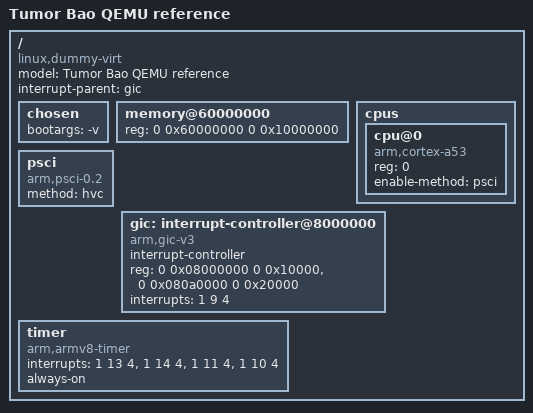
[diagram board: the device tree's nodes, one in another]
/dts-v1/;
/ {
    compatible = "linux,dummy-virt";
    model = "Tumor Bao QEMU reference";
    #address-cells = <2>;
    #size-cells = <2>;
    interrupt-parent = <&gic>;
    chosen { bootargs = "-v"; };
    memory@60000000 { device_type = "memory"; reg = <0 0x60000000 0 0x10000000>; };
    cpus {
        #address-cells = <1>; #size-cells = <0>;
        cpu@0 { device_type = "cpu"; compatible = "arm,cortex-a53"; reg = <0>; enable-method = "psci"; };
    };
    psci { compatible = "arm,psci-0.2"; method = "hvc"; };
    gic: interrupt-controller@8000000 {
        compatible = "arm,gic-v3"; #interrupt-cells = <3>; interrupt-controller;
        #address-cells = <2>; #size-cells = <2>;
        reg = <0 0x08000000 0 0x10000>, <0 0x080a0000 0 0x20000>;
        interrupts = <1 9 4>;
    };
    timer { compatible = "arm,armv8-timer"; interrupts = <1 13 4>, <1 14 4>, <1 11 4>, <1 10 4>; always-on; };
};
